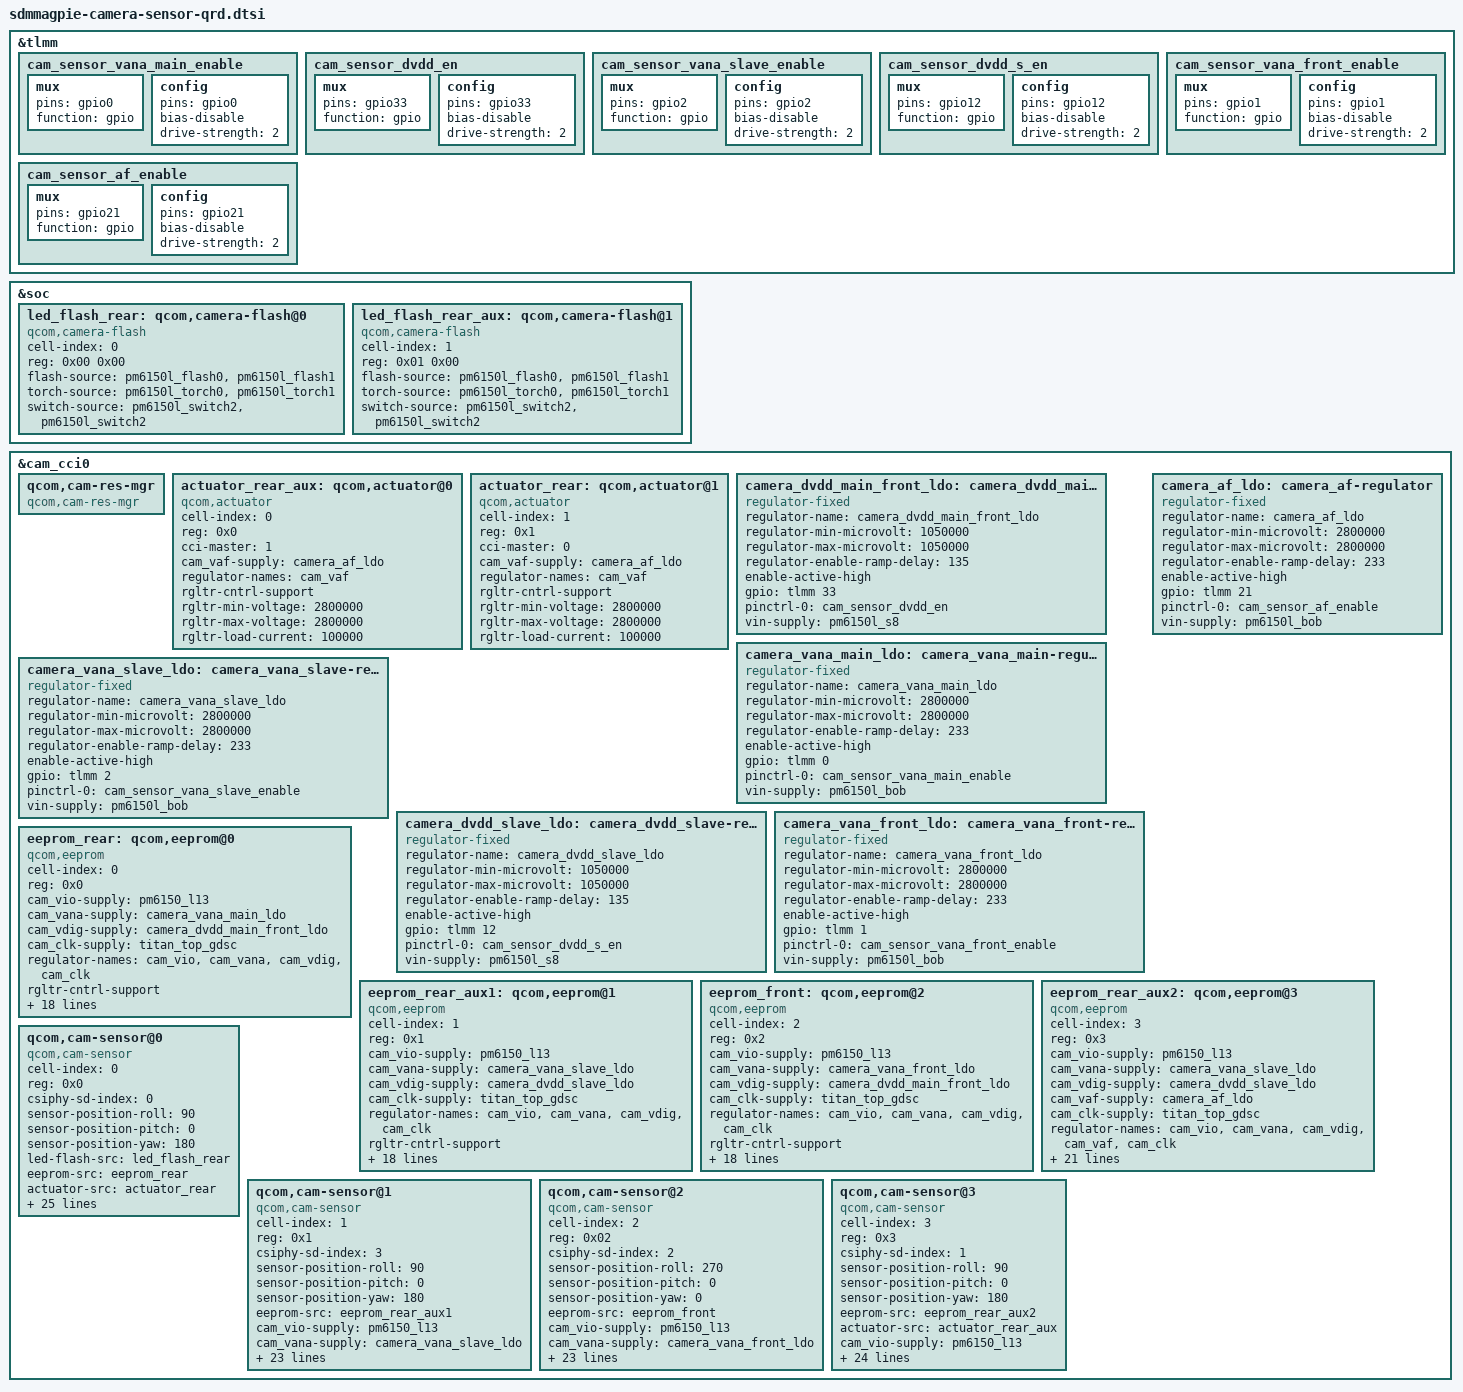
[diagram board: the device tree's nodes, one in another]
/*
 * Copyright (c) 2018, The Linux Foundation. All rights reserved.
 *
 * This program is free software; you can redistribute it and/or modify
 * it under the terms of the GNU General Public License version 2 and
 * only version 2 as published by the Free Software Foundation.
 *
 * This program is distributed in the hope that it will be useful,
 * but WITHOUT ANY WARRANTY; without even the implied warranty of
 * MERCHANTABILITY or FITNESS FOR A PARTICULAR PURPOSE.  See the
 * GNU General Public License for more details.
 */
#include <dt-bindings/clock/qcom,camcc-sdmmagpie.h>

&tlmm {
	cam_sensor_vana_main_enable: cam_sensor_vana_main_enable {
		mux {
			pins = "gpio0";
			function = "gpio";
		};

		config {
			pins = "gpio0";
			bias-disable;
			drive-strength = <2>;
		};
	};

	cam_sensor_dvdd_en: cam_sensor_dvdd_en {
		mux {
			pins = "gpio33";
			function = "gpio";
		};

		config {
			pins = "gpio33";
			bias-disable;
			drive-strength = <2>;
		};
	};
	
	cam_sensor_vana_slave_enable: cam_sensor_vana_slave_enable {
		mux {
			pins = "gpio2";
			function = "gpio";
		};

		config {
			pins = "gpio2";
			bias-disable;
			drive-strength = <2>;
		};
	};

	cam_sensor_dvdd_s_en: cam_sensor_dvdd_s_en {
		mux {
			pins = "gpio12";
			function = "gpio";
		};

		config {
			pins = "gpio12";
			bias-disable;
			drive-strength = <2>;
		};
	};

	cam_sensor_vana_front_enable: cam_sensor_vana_front_enable {
		mux {
			pins = "gpio1";
			function = "gpio";
		};

		config {
			pins = "gpio1";
			bias-disable;
			drive-strength = <2>;
		};
	};
	cam_sensor_af_enable: cam_sensor_af_enable {
		mux {
			pins = "gpio21";
			function = "gpio";
		};

		config {
			pins = "gpio21";
			bias-disable;
			drive-strength = <2>;
		};
	};
};
&soc {
	led_flash_rear: qcom,camera-flash@0 {
		cell-index = <0>;
		reg = <0x00 0x00>;
		compatible = "qcom,camera-flash";
		flash-source = <&pm6150l_flash0 &pm6150l_flash1>;
		torch-source = <&pm6150l_torch0 &pm6150l_torch1>;
		switch-source = <&pm6150l_switch2 &pm6150l_switch2>;
		status = "ok";
	};

	led_flash_rear_aux: qcom,camera-flash@1 {
		cell-index = <1>;
		reg = <0x01 0x00>;
		compatible = "qcom,camera-flash";
		flash-source = <&pm6150l_flash0 &pm6150l_flash1>;
		torch-source = <&pm6150l_torch0 &pm6150l_torch1>;
		switch-source = <&pm6150l_switch2 &pm6150l_switch2>;
		status = "ok";
	};
};

&cam_cci0 {
	qcom,cam-res-mgr {
		compatible = "qcom,cam-res-mgr";
		status = "ok";
	};

	actuator_rear_aux: qcom,actuator@0 {
		cell-index = <0>;
		reg = <0x0>;
		compatible = "qcom,actuator";
		cci-master = <1>;
		cam_vaf-supply = <&camera_af_ldo>;
		regulator-names = "cam_vaf";
		rgltr-cntrl-support;
		rgltr-min-voltage = <2800000>;
		rgltr-max-voltage = <2800000>;
		rgltr-load-current = <100000>;
	};
	actuator_rear: qcom,actuator@1 {
		cell-index = <1>;
		reg = <0x1>;
		compatible = "qcom,actuator";
		cci-master = <0>;
		cam_vaf-supply = <&camera_af_ldo>;
		regulator-names = "cam_vaf";
		rgltr-cntrl-support;
		rgltr-min-voltage = <2800000>;
		rgltr-max-voltage = <2800000>;
		rgltr-load-current = <100000>;
	};
	camera_dvdd_main_front_ldo: camera_dvdd_main_front-regulator {
		compatible = "regulator-fixed";
		regulator-name = "camera_dvdd_main_front_ldo";
		regulator-min-microvolt = <1050000>;
		regulator-max-microvolt = <1050000>;
		regulator-enable-ramp-delay = <135>;
		enable-active-high;
		gpio = <&tlmm 33 0>;
		pinctrl-names = "default";
		pinctrl-0 = <&cam_sensor_dvdd_en>;
		vin-supply = <&pm6150l_s8>;
	};

	camera_vana_main_ldo: camera_vana_main-regulator {
		compatible = "regulator-fixed";
		regulator-name = "camera_vana_main_ldo";
		regulator-min-microvolt = <2800000>;
		regulator-max-microvolt = <2800000>;
		regulator-enable-ramp-delay = <233>;
		enable-active-high;
		gpio = <&tlmm 0 0>;
		pinctrl-names = "default";
		pinctrl-0 = <&cam_sensor_vana_main_enable>;
		vin-supply = <&pm6150l_bob>;
	};

	camera_vana_slave_ldo: camera_vana_slave-regulator {
		compatible = "regulator-fixed";
		regulator-name = "camera_vana_slave_ldo";
		regulator-min-microvolt = <2800000>;
		regulator-max-microvolt = <2800000>;
		regulator-enable-ramp-delay = <233>;
		enable-active-high;
		gpio = <&tlmm 2 0>;
		pinctrl-names = "default";
		pinctrl-0 = <&cam_sensor_vana_slave_enable>;
		vin-supply = <&pm6150l_bob>;
	};

	camera_dvdd_slave_ldo: camera_dvdd_slave-regulator {
		compatible = "regulator-fixed";
		regulator-name = "camera_dvdd_slave_ldo";
		regulator-min-microvolt = <1050000>;
		regulator-max-microvolt = <1050000>;
		regulator-enable-ramp-delay = <135>;
		enable-active-high;
		gpio = <&tlmm 12 0>;
		pinctrl-names = "default";
		pinctrl-0 = <&cam_sensor_dvdd_s_en>;
		vin-supply = <&pm6150l_s8>;
	};

	camera_vana_front_ldo: camera_vana_front-regulator {
		compatible = "regulator-fixed";
		regulator-name = "camera_vana_front_ldo";
		regulator-min-microvolt = <2800000>;
		regulator-max-microvolt = <2800000>;
		regulator-enable-ramp-delay = <233>;
		enable-active-high;
		gpio = <&tlmm 1 0>;
		pinctrl-names = "default";
		pinctrl-0 = <&cam_sensor_vana_front_enable>;
		vin-supply = <&pm6150l_bob>;
	};

	camera_af_ldo: camera_af-regulator {
		compatible = "regulator-fixed";
		regulator-name = "camera_af_ldo";
		regulator-min-microvolt = <2800000>;
		regulator-max-microvolt = <2800000>;
		regulator-enable-ramp-delay = <233>;
		enable-active-high;
		gpio = <&tlmm 21 0>;
		pinctrl-names = "default";
		pinctrl-0 = <&cam_sensor_af_enable>;
		vin-supply = <&pm6150l_bob>;
	};

	eeprom_rear: qcom,eeprom@0 {
		cell-index = <0>;
		reg = <0x0>;
		compatible = "qcom,eeprom";
		cam_vio-supply = <&pm6150_l13>;
		cam_vana-supply = <&camera_vana_main_ldo>;
		cam_vdig-supply = <&camera_dvdd_main_front_ldo>;
		cam_clk-supply = <&titan_top_gdsc>;
		regulator-names = "cam_vio", "cam_vana", "cam_vdig",
			"cam_clk";
		rgltr-cntrl-support;
		rgltr-min-voltage = <1800000 2800000 1050000 0>;
		rgltr-max-voltage = <1800000 2800000 1050000 0>;
		rgltr-load-current = <0 80000 105000 0>;
		gpio-no-mux = <0>;
		pinctrl-names = "cam_default", "cam_suspend";
		pinctrl-0 = <&cam_sensor_mclk0_active
				&cam_sensor_rear_active>;
		pinctrl-1 = <&cam_sensor_mclk0_suspend
				&cam_sensor_rear_suspend>;
		gpios = <&tlmm 13 0>,
			<&tlmm 23 0>;
		gpio-reset = <1>;
		gpio-req-tbl-num = <0 1>;
		gpio-req-tbl-flags = <1 0>;
		gpio-req-tbl-label = "CAMIF_MCLK0",
					"CAM_RESET0";
		sensor-mode = <0>;
		cci-master = <0>;
		status = "ok";
		clocks = <&clock_camcc CAM_CC_MCLK0_CLK>;
		clock-names = "cam_clk";
		clock-cntl-level = "turbo";
		clock-rates = <24000000>;
	};

	eeprom_rear_aux1: qcom,eeprom@1 {
		cell-index = <1>;
		reg = <0x1>;
		compatible = "qcom,eeprom";
		cam_vio-supply = <&pm6150_l13>;
		cam_vana-supply = <&camera_vana_slave_ldo>;
		cam_vdig-supply = <&camera_dvdd_slave_ldo>;
		cam_clk-supply = <&titan_top_gdsc>;
		regulator-names = "cam_vio", "cam_vana", "cam_vdig",
			"cam_clk";
		rgltr-cntrl-support;
		rgltr-min-voltage = <1800000 2800000 1050000 0>;
		rgltr-max-voltage = <1800000 2800000 1050000 0>;
		rgltr-load-current = <105000 0 80000 0>;
		gpio-no-mux = <0>;
		pinctrl-names = "cam_default", "cam_suspend";
		pinctrl-0 = <&cam_sensor_mclk3_active
				&cam_sensor_rear3_active>;
		pinctrl-1 = <&cam_sensor_mclk3_suspend
				&cam_sensor_rear3_suspend>;
		gpios = <&tlmm 16 0>,
			<&tlmm 26 0>;
		gpio-reset = <1>;
		gpio-req-tbl-num = <0 1>;
		gpio-req-tbl-flags = <1 0>;
		gpio-req-tbl-label = "CAMIF_MCLK3",
					"CAM_RESET3";
		sensor-mode = <0>;
		cci-master = <1>;
		status = "ok";
		clocks = <&clock_camcc CAM_CC_MCLK3_CLK>;
		clock-names = "cam_clk";
		clock-cntl-level = "turbo";
		clock-rates = <24000000>;
	};

	eeprom_front: qcom,eeprom@2 {
		cell-index = <2>;
		reg = <0x2>;
		compatible = "qcom,eeprom";
		cam_vio-supply = <&pm6150_l13>;
		cam_vana-supply = <&camera_vana_front_ldo>;
		cam_vdig-supply = <&camera_dvdd_main_front_ldo>;
		cam_clk-supply = <&titan_top_gdsc>;
		regulator-names = "cam_vio", "cam_vana", "cam_vdig",
			"cam_clk";
		rgltr-cntrl-support;
		rgltr-min-voltage = <1800000 2800000 1050000 0>;
		rgltr-max-voltage = <1800000 2800000 1050000 0>;
		rgltr-load-current = <0 80000 105000 0>;
		gpio-no-mux = <0>;
		pinctrl-names = "cam_default", "cam_suspend";
		pinctrl-0 = <&cam_sensor_mclk2_active
				 &cam_sensor_front_active>;
		pinctrl-1 = <&cam_sensor_mclk2_suspend
				 &cam_sensor_front_suspend>;
		gpios = <&tlmm 15 0>,
			<&tlmm 25 0>;
		gpio-reset = <1>;
		gpio-req-tbl-num = <0 1>;
		gpio-req-tbl-flags = <1 0>;
		gpio-req-tbl-label = "CAMIF_MCLK2",
					"CAM_RESET2";
		sensor-mode = <0>;
		cci-master = <1>;
		status = "ok";
		clocks = <&clock_camcc CAM_CC_MCLK2_CLK>;
		clock-names = "cam_clk";
		clock-cntl-level = "turbo";
		clock-rates = <24000000>;
	};

	eeprom_rear_aux2: qcom,eeprom@3 {
		cell-index = <3>;
		reg = <0x3>;
		compatible = "qcom,eeprom";
		cam_vio-supply = <&pm6150_l13>;
		cam_vana-supply = <&camera_vana_slave_ldo>;
		cam_vdig-supply = <&camera_dvdd_slave_ldo>;
		cam_vaf-supply = <&camera_af_ldo>;
		cam_clk-supply = <&titan_top_gdsc>;
		regulator-names = "cam_vio", "cam_vana", "cam_vdig", "cam_vaf",
			"cam_clk";
		rgltr-cntrl-support;
		rgltr-min-voltage = <1800000 2800000 1050000 2800000 0>;
		rgltr-max-voltage = <1800000 2800000 1050000 2800000 0>;
		rgltr-load-current = <105000 0 80000 100000 0>;
		gpio-no-mux = <0>;
		pinctrl-names = "cam_default", "cam_suspend";
		pinctrl-0 = <&cam_sensor_mclk1_active
				&cam_sensor_rear2_active>;
		pinctrl-1 = <&cam_sensor_mclk1_suspend
				&cam_sensor_rear2_suspend>;
		gpios = <&tlmm 14 0>,
			<&tlmm 24 0>;
		gpio-reset = <1>;
		gpio-req-tbl-num = <0 1>;
		gpio-req-tbl-flags = <1 0>;
		gpio-req-tbl-label = "CAMIF_MCLK1",
					"CAM_RESET1";
		sensor-mode = <0>;
		cci-master = <1>;
		status = "ok";
		clocks = <&clock_camcc CAM_CC_MCLK1_CLK>;
		clock-names = "cam_clk";
		clock-cntl-level = "turbo";
		clock-rates = <24000000>;
	};

	qcom,cam-sensor@0 {
		cell-index = <0>;
		compatible = "qcom,cam-sensor";
		reg = <0x0>;
		csiphy-sd-index = <0>;
		sensor-position-roll = <90>;
		sensor-position-pitch = <0>;
		sensor-position-yaw = <180>;
		led-flash-src = <&led_flash_rear>;
		eeprom-src = <&eeprom_rear>;
		actuator-src = <&actuator_rear>;
		cam_vio-supply = <&pm6150_l13>;
		cam_vana-supply = <&camera_vana_main_ldo>;
		cam_vdig-supply = <&camera_dvdd_main_front_ldo>;
		cam_clk-supply = <&titan_top_gdsc>;
		regulator-names = "cam_vio", "cam_vana", "cam_vdig",
			"cam_clk";
		rgltr-cntrl-support;
		rgltr-min-voltage = <1800000 2800000 1050000 0>;
		rgltr-max-voltage = <1800000 2800000 1050000 0>;
		rgltr-load-current = <0 80000 105000 0>;
		gpio-no-mux = <0>;
		pinctrl-names = "cam_default", "cam_suspend";
		pinctrl-0 = <&cam_sensor_mclk0_active
				&cam_sensor_rear_active>;
		pinctrl-1 = <&cam_sensor_mclk0_suspend
				&cam_sensor_rear_suspend>;
		gpios = <&tlmm 13 0>,
			<&tlmm 23 0>;
		gpio-reset = <1>;
		gpio-req-tbl-num = <0 1>;
		gpio-req-tbl-flags = <1 0>;
		gpio-req-tbl-label = "CAMIF_MCLK0",
					"CAM_RESET0";
		sensor-mode = <0>;
		cci-master = <0>;
		status = "ok";
		clocks = <&clock_camcc CAM_CC_MCLK0_CLK>;
		clock-names = "cam_clk";
		clock-cntl-level = "turbo";
		clock-rates = <24000000>;
	};

	qcom,cam-sensor@1 {
		cell-index = <1>;
		compatible = "qcom,cam-sensor";
		reg = <0x1>;
		csiphy-sd-index = <3>;
		sensor-position-roll = <90>;
		sensor-position-pitch = <0>;
		sensor-position-yaw = <180>;
		eeprom-src = <&eeprom_rear_aux1>;
		cam_vio-supply = <&pm6150_l13>;
		cam_vana-supply = <&camera_vana_slave_ldo>;
		cam_vdig-supply = <&camera_dvdd_slave_ldo>;
		cam_clk-supply = <&titan_top_gdsc>;
		regulator-names = "cam_vio", "cam_vana", "cam_vdig",
			"cam_clk";
		rgltr-cntrl-support;
		rgltr-min-voltage = <1800000 2800000 1050000 0>;
		rgltr-max-voltage = <1800000 2800000 1050000 0>;
		rgltr-load-current = <105000 0 80000 0>;
		gpio-no-mux = <0>;
		pinctrl-names = "cam_default", "cam_suspend";
		pinctrl-0 = <&cam_sensor_mclk3_active
				&cam_sensor_rear3_active>;
		pinctrl-1 = <&cam_sensor_mclk3_suspend
				&cam_sensor_rear3_suspend>;
		gpios = <&tlmm 16 0>,
			<&tlmm 26 0>;
		gpio-reset = <1>;
		gpio-req-tbl-num = <0 1>;
		gpio-req-tbl-flags = <1 0>;
		gpio-req-tbl-label = "CAMIF_MCLK3",
					"CAM_RESET3";
		sensor-mode = <0>;
		cci-master = <1>;
		status = "ok";
		clocks = <&clock_camcc CAM_CC_MCLK3_CLK>;
		clock-names = "cam_clk";
		clock-cntl-level = "turbo";
		clock-rates = <24000000>;
	};

	qcom,cam-sensor@2 {
		cell-index = <2>;
		compatible = "qcom,cam-sensor";
		reg = <0x02>;
		csiphy-sd-index = <2>;
		sensor-position-roll = <270>;
		sensor-position-pitch = <0>;
		sensor-position-yaw = <0>;
		eeprom-src = <&eeprom_front>;
		cam_vio-supply = <&pm6150_l13>;
		cam_vana-supply = <&camera_vana_front_ldo>;
		cam_vdig-supply = <&camera_dvdd_main_front_ldo>;
		cam_clk-supply = <&titan_top_gdsc>;
		regulator-names = "cam_vio", "cam_vana", "cam_vdig",
			"cam_clk";
		rgltr-cntrl-support;
		rgltr-min-voltage = <1800000 2800000 1050000 0>;
		rgltr-max-voltage = <1800000 2800000 1050000 0>;
		rgltr-load-current = <0 80000 105000 0>;
		gpio-no-mux = <0>;
		pinctrl-names = "cam_default", "cam_suspend";
		pinctrl-0 = <&cam_sensor_mclk2_active
				 &cam_sensor_front_active>;
		pinctrl-1 = <&cam_sensor_mclk2_suspend
				 &cam_sensor_front_suspend>;
		gpios = <&tlmm 15 0>,
			<&tlmm 25 0>;
		gpio-reset = <1>;
		gpio-req-tbl-num = <0 1>;
		gpio-req-tbl-flags = <1 0>;
		gpio-req-tbl-label = "CAMIF_MCLK2",
					"CAM_RESET2";
		sensor-mode = <0>;
		cci-master = <1>;
		status = "ok";
		clocks = <&clock_camcc CAM_CC_MCLK2_CLK>;
		clock-names = "cam_clk";
		clock-cntl-level = "turbo";
		clock-rates = <24000000>;
	};

	qcom,cam-sensor@3 {
		cell-index = <3>;
		compatible = "qcom,cam-sensor";
		reg = <0x3>;
		csiphy-sd-index = <1>;
		sensor-position-roll = <90>;
		sensor-position-pitch = <0>;
		sensor-position-yaw = <180>;
		eeprom-src = <&eeprom_rear_aux2>;
		actuator-src = <&actuator_rear_aux>;
		cam_vio-supply = <&pm6150_l13>;
		cam_vana-supply = <&camera_vana_slave_ldo>;
		cam_vdig-supply = <&camera_dvdd_slave_ldo>;
		cam_clk-supply = <&titan_top_gdsc>;
		regulator-names = "cam_vio", "cam_vana", "cam_vdig",
			"cam_clk";
		rgltr-cntrl-support;
		rgltr-min-voltage = <1800000 2800000 1050000 0>;
		rgltr-max-voltage = <1800000 2800000 1050000 0>;
		rgltr-load-current = <105000 0 80000 0>;
		gpio-no-mux = <0>;
		pinctrl-names = "cam_default", "cam_suspend";
		pinctrl-0 = <&cam_sensor_mclk1_active
				&cam_sensor_rear2_active>;
		pinctrl-1 = <&cam_sensor_mclk1_suspend
				&cam_sensor_rear2_suspend>;
		gpios = <&tlmm 14 0>,
			<&tlmm 24 0>;
		gpio-reset = <1>;
		gpio-req-tbl-num = <0 1>;
		gpio-req-tbl-flags = <1 0>;
		gpio-req-tbl-label = "CAMIF_MCLK1",
					"CAM_RESET1";
		sensor-mode = <0>;
		cci-master = <1>;
		status = "ok";
		clocks = <&clock_camcc CAM_CC_MCLK1_CLK>;
		clock-names = "cam_clk";
		clock-cntl-level = "turbo";
		clock-rates = <24000000>;
	};
};
